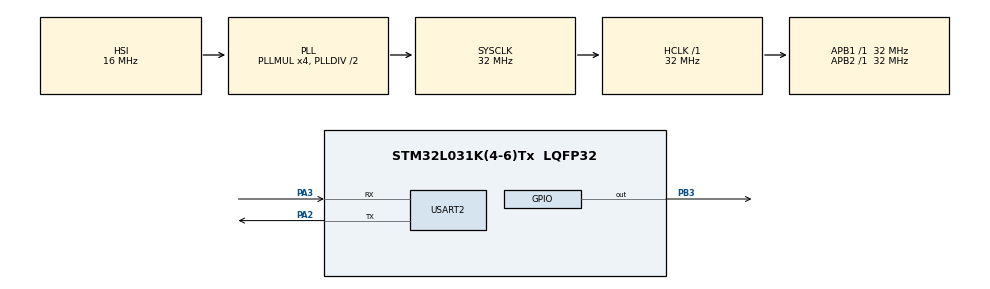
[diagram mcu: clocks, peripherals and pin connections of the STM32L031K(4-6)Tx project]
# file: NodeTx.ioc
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Dma.Request0=USART2_RX
Dma.USART2_RX.0.Direction=DMA_PERIPH_TO_MEMORY
Dma.USART2_RX.0.Instance=DMA1_Channel5
Dma.USART2_RX.0.MemDataAlignment=DMA_MDATAALIGN_BYTE
Dma.USART2_RX.0.MemInc=DMA_MINC_ENABLE
Dma.USART2_RX.0.Mode=DMA_NORMAL
Dma.USART2_RX.0.PeriphDataAlignment=DMA_PDATAALIGN_BYTE
Dma.USART2_RX.0.PeriphInc=DMA_PINC_DISABLE
Dma.USART2_RX.0.Priority=DMA_PRIORITY_LOW
Mcu.Family=STM32L0
Mcu.Name=STM32L031K(4-6)Tx
Mcu.Package=LQFP32
NVIC.DMA1_Channel4_5_6_7_IRQn=true\:0\:0\:false\:false\:true\:false\:true\:true
NVIC.USART2_IRQn=true\:0\:0\:false\:false\:true\:true\:true\:true
PA13.Mode=Serial_Wire
PA13.Signal=SYS_SWDIO
PA14.Mode=Serial_Wire
PA14.Signal=SYS_SWCLK
PA2.Mode=Asynchronous
PA2.Signal=USART2_TX
PA3.Mode=Asynchronous
PA3.Signal=USART2_RX
PB3.Signal=GPIO_Output
ProjectManager.HeapSize=0x200
ProjectManager.StackSize=0x400
ProjectManager.TargetToolchain=STM32CubeIDE
RCC.AHBFreq_Value=32000000
RCC.APB1Freq_Value=32000000
RCC.APB1TimFreq_Value=32000000
RCC.APB2Freq_Value=32000000
RCC.APB2TimFreq_Value=32000000
RCC.HCLKFreq_Value=32000000
RCC.HSE_VALUE=8000000
RCC.HSI16_VALUE=16000000
RCC.HSI48_VALUE=48000000
RCC.HSI_VALUE=16000000
RCC.MSI_VALUE=2097000
RCC.PLLMUL=RCC_PLLMUL_4
RCC.SYSCLKFreq_VALUE=32000000
RCC.SYSCLKSource=RCC_SYSCLKSOURCE_PLLCLK
RCC.VCOOutputFreq_Value=64000000
USART2.VirtualMode-Asynchronous=VM_ASYNC
board=NUCLEO-L031K6

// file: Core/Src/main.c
/* USER CODE BEGIN Header */
/**
  ******************************************************************************
  * @file           : main.c
  * @brief          : Main program body
  ******************************************************************************
  * @attention
  *
  * Copyright (c) 2026 STMicroelectronics.
  * All rights reserved.
  *
  * This software is licensed under terms that can be found in the LICENSE file
  * in the root directory of this software component.
  * If no LICENSE file comes with this software, it is provided AS-IS.
  *
  ******************************************************************************
  */
/* USER CODE END Header */
#include "main.h"

/* USER CODE BEGIN Includes */
#include "stdio.h"
#include "string.h"
#include "SX1262.h"
/* USER CODE END Includes */

UART_HandleTypeDef huart2;
DMA_HandleTypeDef hdma_usart2_rx;

/* USER CODE BEGIN PV */
extern uint8_t rxBuffer[32];

int size;
volatile uint8_t status = 0;

uint32_t val;
/* USER CODE END PV */

void SystemClock_Config(void);
static void MX_GPIO_Init(void);
static void MX_DMA_Init(void);
static void MX_USART2_UART_Init(void);

/* USER CODE BEGIN 0 */
void HAL_UARTEx_RxEventCallback(UART_HandleTypeDef *huart, uint16_t Size)
{
	size = Size;
	if(huart -> Instance == USART2)
	{
		__HAL_DMA_DISABLE_IT(huart2.hdmarx, DMA_IT_HT);
	}
}
/* USER CODE END 0 */

int main(void)
{

  /* MCU Configuration--------------------------------------------------------*/

  /* Reset of all peripherals, Initializes the Flash interface and the Systick. */
  HAL_Init();

  /* Configure the system clock */
  SystemClock_Config();

  /* Initialize all configured peripherals */
  MX_GPIO_Init();
  MX_DMA_Init();
  MX_USART2_UART_Init();
  /* USER CODE BEGIN 2 */

  SX1262_Init();

  SX1262_Set_LPCFG();
  SX1262_Get_LPCFG();

  SX1262_Receive();

  SX1262_Stop();

  /* USER CODE END 2 */

  /* Infinite loop */
  while (1)
  {
	  SX1262_Send();
	  HAL_Delay(2000);
  }
}

void SystemClock_Config(void)
{
  RCC_OscInitTypeDef RCC_OscInitStruct = {0};
  RCC_ClkInitTypeDef RCC_ClkInitStruct = {0};
  RCC_PeriphCLKInitTypeDef PeriphClkInit = {0};

  /** Configure the main internal regulator output voltage
  */
  __HAL_PWR_VOLTAGESCALING_CONFIG(PWR_REGULATOR_VOLTAGE_SCALE1);

  /** Initializes the RCC Oscillators according to the specified parameters
  * in the RCC_OscInitTypeDef structure.
  */
  RCC_OscInitStruct.OscillatorType = RCC_OSCILLATORTYPE_HSI;
  RCC_OscInitStruct.HSIState = RCC_HSI_ON;
  RCC_OscInitStruct.HSICalibrationValue = RCC_HSICALIBRATION_DEFAULT;
  RCC_OscInitStruct.PLL.PLLState = RCC_PLL_ON;
  RCC_OscInitStruct.PLL.PLLSource = RCC_PLLSOURCE_HSI;
  RCC_OscInitStruct.PLL.PLLMUL = RCC_PLLMUL_4;
  RCC_OscInitStruct.PLL.PLLDIV = RCC_PLLDIV_2;
  if (HAL_RCC_OscConfig(&RCC_OscInitStruct) != HAL_OK)
  {
    Error_Handler();
  }

  /** Initializes the CPU, AHB and APB buses clocks
  */
  RCC_ClkInitStruct.ClockType = RCC_CLOCKTYPE_HCLK|RCC_CLOCKTYPE_SYSCLK
                              |RCC_CLOCKTYPE_PCLK1|RCC_CLOCKTYPE_PCLK2;
  RCC_ClkInitStruct.SYSCLKSource = RCC_SYSCLKSOURCE_PLLCLK;
  RCC_ClkInitStruct.AHBCLKDivider = RCC_SYSCLK_DIV1;
  RCC_ClkInitStruct.APB1CLKDivider = RCC_HCLK_DIV1;
  RCC_ClkInitStruct.APB2CLKDivider = RCC_HCLK_DIV1;

  if (HAL_RCC_ClockConfig(&RCC_ClkInitStruct, FLASH_LATENCY_1) != HAL_OK)
  {
    Error_Handler();
  }
  PeriphClkInit.PeriphClockSelection = RCC_PERIPHCLK_USART2;
  PeriphClkInit.Usart2ClockSelection = RCC_USART2CLKSOURCE_PCLK1;
  if (HAL_RCCEx_PeriphCLKConfig(&PeriphClkInit) != HAL_OK)
  {
    Error_Handler();
  }
}

static void MX_USART2_UART_Init(void)
{

  huart2.Instance = USART2;
  huart2.Init.BaudRate = 115200;
  huart2.Init.WordLength = UART_WORDLENGTH_8B;
  huart2.Init.StopBits = UART_STOPBITS_1;
  huart2.Init.Parity = UART_PARITY_NONE;
  huart2.Init.Mode = UART_MODE_TX_RX;
  huart2.Init.HwFlowCtl = UART_HWCONTROL_NONE;
  huart2.Init.OverSampling = UART_OVERSAMPLING_16;
  huart2.Init.OneBitSampling = UART_ONE_BIT_SAMPLE_DISABLE;
  huart2.AdvancedInit.AdvFeatureInit = UART_ADVFEATURE_NO_INIT;
  if (HAL_UART_Init(&huart2) != HAL_OK)
  {
    Error_Handler();
  }

}

static void MX_DMA_Init(void)
{

  /* DMA controller clock enable */
  __HAL_RCC_DMA1_CLK_ENABLE();

  /* DMA interrupt init */
  /* DMA1_Channel4_5_6_7_IRQn interrupt configuration */
  HAL_NVIC_SetPriority(DMA1_Channel4_5_6_7_IRQn, 0, 0);
  HAL_NVIC_EnableIRQ(DMA1_Channel4_5_6_7_IRQn);

}

static void MX_GPIO_Init(void)
{
  GPIO_InitTypeDef GPIO_InitStruct = {0};

  /* GPIO Ports Clock Enable */
  __HAL_RCC_GPIOA_CLK_ENABLE();
  __HAL_RCC_GPIOB_CLK_ENABLE();

  /*Configure GPIO pin Output Level */
  HAL_GPIO_WritePin(GPIOB, GPIO_PIN_3, GPIO_PIN_RESET);

  /*Configure GPIO pin : PB3 */
  GPIO_InitStruct.Pin = GPIO_PIN_3;
  GPIO_InitStruct.Mode = GPIO_MODE_OUTPUT_PP;
  GPIO_InitStruct.Pull = GPIO_NOPULL;
  GPIO_InitStruct.Speed = GPIO_SPEED_FREQ_LOW;
  HAL_GPIO_Init(GPIOB, &GPIO_InitStruct);

}

void Error_Handler(void)
{
  __disable_irq();
  while (1)
  {
  }
}
